# AT91SAM9M10 register map
Vendor: Atmel; File version: 20130207
CPU: 
Registers are 32-bit, read-write, no defined reset value unless marked. A register's access mark holds for its fields unless they carry their own. Offsets are from the block's base; [hi:lo] are bit positions; {n}, {i} and the like mark numbered series; 'fields as' and 'values as' point back to an identical list.

## AC97C — AC97 Controller
Base 0xFFFAC000; register names take the prefix AC97C_
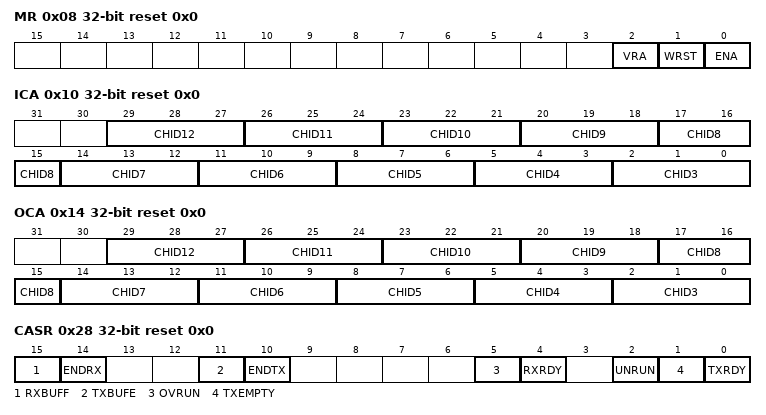
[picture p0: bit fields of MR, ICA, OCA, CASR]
0x08 MR reset 0x0 — Mode Register
  [2] VRA — Variable Rate (for Data Slots 3-12)
  [1] WRST — Warm Reset
  [0] ENA — AC97 Controller Global Enable
0x10 ICA reset 0x0 — Input Channel Assignment Register
  [3n-7:3n-9] CHID{n} (n=3..12) — Channel ID for the input slot {n}
0x14 OCA reset 0x0 — Output Channel Assignment Register
  [3n-7:3n-9] CHID{n} (n=3..12) — Channel ID for the output slot {n}
0x20 CARHR ro reset 0x0 — Channel A Receive Holding Register
  [19:0] RDATA — Receive Data
0x24 CATHR wo — Channel A Transmit Holding Register
  [19:0] TDATA — Transmit Data
0x28 CASR ro reset 0x0 — Channel A Status Register
  [15] RXBUFF — Receive Buffer Full for Channel A
  [14] ENDRX — End of Reception for Channel A
  [11] TXBUFE — Transmit Buffer Empty for Channel A
  [10] ENDTX — End of Transmission for Channel A
  [5] OVRUN — Receive Overrun
  [4] RXRDY — Channel Receive Ready
  [2] UNRUN — Transmit Underrun
  [1] TXEMPTY — Channel Transmit Empty
  [0] TXRDY — Channel Transmit Ready
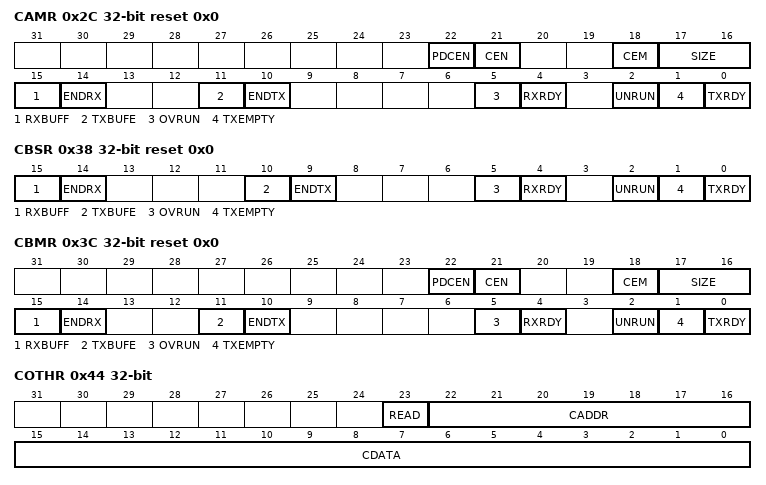
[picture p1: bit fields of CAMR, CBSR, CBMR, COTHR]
0x2C CAMR reset 0x0 — Channel A Mode Register
  [22] PDCEN — Peripheral Data Controller Channel Enable
  [21] CEN — Channel A Enable
  [18] CEM — Channel A Endian Mode
  [17:16] SIZE — Channel A Data Size
  [15] RXBUFF — Receive Buffer Full for Channel A Interrupt Enable
  [14] ENDRX — End of Reception for Channel A Interrupt Enable
  [11] TXBUFE — Transmit Buffer Empty for Channel A Interrupt Enable
  [10] ENDTX — End of Transmission for Channel A Interrupt Enable
  [5] OVRUN — Receive Overrun Interrupt Enable
  [4] RXRDY — Channel Receive Ready Interrupt Enable
  [2] UNRUN — Transmit Underrun Interrupt Enable
  [1] TXEMPTY — Channel Transmit Empty Interrupt Enable
  [0] TXRDY — Channel Transmit Ready Interrupt Enable
0x30 CBRHR ro reset 0x0 — Channel B Receive Holding Register
  [19:0] RDATA — Receive Data
0x34 CBTHR wo — Channel B Transmit Holding Register
  [19:0] TDATA — Transmit Data
0x38 CBSR ro reset 0x0 — Channel B Status Register
  [15] RXBUFF — Receive Buffer Full for Channel B
  [14] ENDRX — End of Reception for Channel B
  [10] TXBUFE — Transmit Buffer Empty for Channel B
  [9] ENDTX — End of Transmission for Channel B
  [5] OVRUN — Receive Overrun
  [4] RXRDY — Channel Receive Ready
  [2] UNRUN — Transmit Underrun
  [1] TXEMPTY — Channel Transmit Empty
  [0] TXRDY — Channel Transmit Ready
0x3C CBMR reset 0x0 — Channel B Mode Register
  [22] PDCEN — Peripheral Data Controller Channel Enable
  [21] CEN — Channel B Enable
  [18] CEM — Channel B Endian Mode
  [17:16] SIZE — Channel B Data Size
  [15] RXBUFF — Receive Buffer Full for Channel B Interrupt Enable
  [14] ENDRX — End of Reception for Channel B Interrupt Enable
  [11] TXBUFE — Transmit Buffer Empty for Channel B Interrupt Enable
  [10] ENDTX — End of Transmission for Channel B Interrupt Enable
  [5] OVRUN — Receive Overrun Interrupt Enable
  [4] RXRDY — Channel Receive Ready Interrupt Enable
  [2] UNRUN — Transmit Underrun Interrupt Enable
  [1] TXEMPTY — Channel Transmit Empty Interrupt Enable
  [0] TXRDY — Channel Transmit Ready Interrupt Enable
0x40 CORHR ro reset 0x0 — Codec Channel Receive Holding Register
  [15:0] SDATA — Status Data
0x44 COTHR wo — Codec Channel Transmit Holding Register
  [23] READ — Read-write command
  [22:16] CADDR — CODEC control register index
  [15:0] CDATA — Command Data
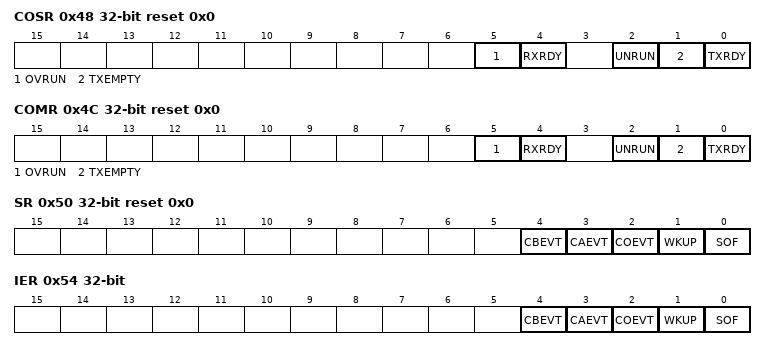
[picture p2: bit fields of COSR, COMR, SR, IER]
0x48 COSR ro reset 0x0 — Codec Status Register
  [5] OVRUN — Receive Overrun
  [4] RXRDY — Channel Receive Ready
  [2] UNRUN — Transmit Underrun
  [1] TXEMPTY — Channel Transmit Empty
  [0] TXRDY — Channel Transmit Ready
0x4C COMR reset 0x0 — Codec Mode Register
  [5] OVRUN — Receive Overrun Interrupt Enable
  [4] RXRDY — Channel Receive Ready Interrupt Enable
  [2] UNRUN — Transmit Underrun Interrupt Enable
  [1] TXEMPTY — Channel Transmit Empty Interrupt Enable
  [0] TXRDY — Channel Transmit Ready Interrupt Enable
0x50 SR ro reset 0x0 — Status Register
  [4] CBEVT — Channel B Event
  [3] CAEVT — Channel A Event
  [2] COEVT — CODEC Channel Event
  [1] WKUP — Wake Up detection
  [0] SOF — Start Of Frame
0x54 IER wo — Interrupt Enable Register
  [4] CBEVT — Channel B Event
  [3] CAEVT — Channel A Event
  [2] COEVT — Codec Event
  [1] WKUP — Wake Up
  [0] SOF — Start Of Frame
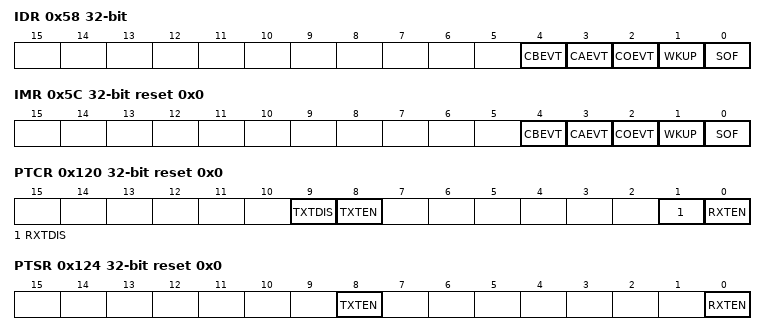
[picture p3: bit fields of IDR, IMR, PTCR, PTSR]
0x58 IDR wo — Interrupt Disable Register
  fields as IER
0x5C IMR ro reset 0x0 — Interrupt Mask Register
  fields as IER
0x100 RPR reset 0x0 — Receive Pointer Register
  [31:0] RXPTR
0x104 RCR reset 0x0 — Receive Counter Register
  [15:0] RXCTR
0x108 TPR reset 0x0 — Transmit Pointer Register
  [31:0] TXPTR — Transmit Counter Register
0x10C TCR reset 0x0 — Transmit Counter Register
  [15:0] TXCTR
0x110 RNPR reset 0x0 — Receive Next Pointer Register
  [31:0] RXNPTR — Receive Next Pointer
0x114 RNCR reset 0x0 — Receive Next Counter Register
  [15:0] RXNCTR — Receive Next Counter
0x118 TNPR reset 0x0 — Transmit Next Pointer Register
  [31:0] TXNPTR — Transmit Next Pointer
0x11C TNCR reset 0x0 — Transmit Next Counter Register
  [15:0] TXNCTR — Transmit Counter Next
0x120 PTCR wo reset 0x0 — Transfer Control Register
  [9] TXTDIS — Transmitter Transfer Disable
  [8] TXTEN — Transmitter Transfer Enable
  [1] RXTDIS — Receiver Transfer Disable
  [0] RXTEN — Receiver Transfer Enable
0x124 PTSR ro reset 0x0 — Transfer Status Register
  [8] TXTEN — Transmitter Transfer Enable
  [0] RXTEN — Receiver Transfer Enable
